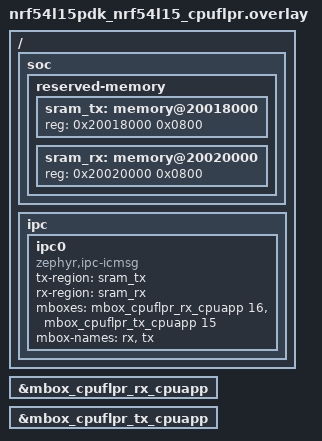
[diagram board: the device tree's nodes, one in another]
/*
 * Copyright (c) 2024 Nordic Semiconductor ASA
 *
 * SPDX-License-Identifier: Apache-2.0
 */

/ {
	soc {
		reserved-memory {
			#address-cells = <1>;
			#size-cells = <1>;

			sram_tx: memory@20018000 {
				reg = <0x20018000 0x0800>;
			};

			sram_rx: memory@20020000 {
				reg = <0x20020000 0x0800>;
			};
		};
	};

	ipc {
		ipc0: ipc0 {
			compatible = "zephyr,ipc-icmsg";
			tx-region = <&sram_tx>;
			rx-region = <&sram_rx>;
			mboxes = <&mbox_cpuflpr_rx_cpuapp 16>, <&mbox_cpuflpr_tx_cpuapp 15>;
			mbox-names = "rx", "tx";
			status = "okay";
		};
	};
};

&mbox_cpuflpr_rx_cpuapp {
	status = "okay";
};

&mbox_cpuflpr_tx_cpuapp {
	status = "okay";
};
